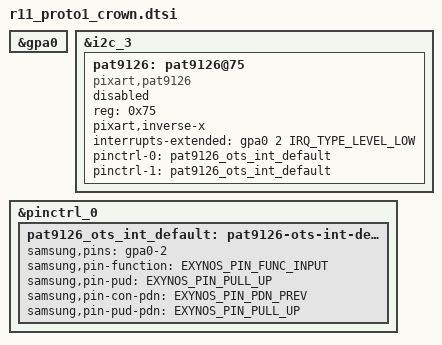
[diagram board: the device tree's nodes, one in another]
/*
 * Device Tree config for the PAT9126 chip - optical tracking sensor (RSB)
 */
#include <dt-bindings/interrupt-controller/irq.h>

&gpa0 {
	#interrupt-cells = <2>;
};

&i2c_3 {
	#address-cells = <1>;
	#size-cells = <0>;
	status = "ok";

	pat9126: pat9126@75 {
		compatible="pixart,pat9126";
		status = "disabled";
		reg = <0x75>;
		pixart,inverse-x;
		interrupts-extended = <&gpa0 2 IRQ_TYPE_LEVEL_LOW>;
		pinctrl-names = "default", "sleep";
		pinctrl-0 = <&pat9126_ots_int_default>;
		pinctrl-1 = <&pat9126_ots_int_default>;
	};
};

&pinctrl_0 {
	/* OTS Interrupt Pinctrl */
	pat9126_ots_int_default: pat9126-ots-int-default {
		samsung,pins = "gpa0-2";
		samsung,pin-function = <EXYNOS_PIN_FUNC_INPUT>;
		samsung,pin-pud = <EXYNOS_PIN_PULL_UP>;
		samsung,pin-con-pdn = <EXYNOS_PIN_PDN_PREV>;
		samsung,pin-pud-pdn = <EXYNOS_PIN_PULL_UP>;
	};
};
